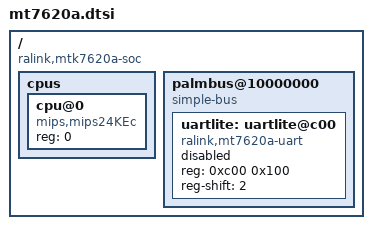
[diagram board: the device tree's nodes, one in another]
/* based on linux/arch/mips/boot/dts/ralink/mt7620a.dtsi */

/dts-v1/;

/ {
	#address-cells = <1>;
	#size-cells = <1>;
	compatible = "ralink,mtk7620a-soc";

	cpus {
		#address-cells = <1>;
		#size-cells = <0>;

		cpu@0 {
			device_type = "cpu";
			compatible = "mips,mips24KEc";
			reg = <0>;
		};
	};

	palmbus@10000000 {
		compatible = "simple-bus";
                ranges = <0x0 0x10000000 0x1FFFFF>;

		#address-cells = <1>;
		#size-cells = <1>;

		uartlite: uartlite@c00 {
			compatible = "ralink,mt7620a-uart", "ralink,rt2880-uart", "ns16550a";
			reg = <0xc00 0x100>;

			reg-shift = <2>;

			status = "disabled";
		};
	};
};
